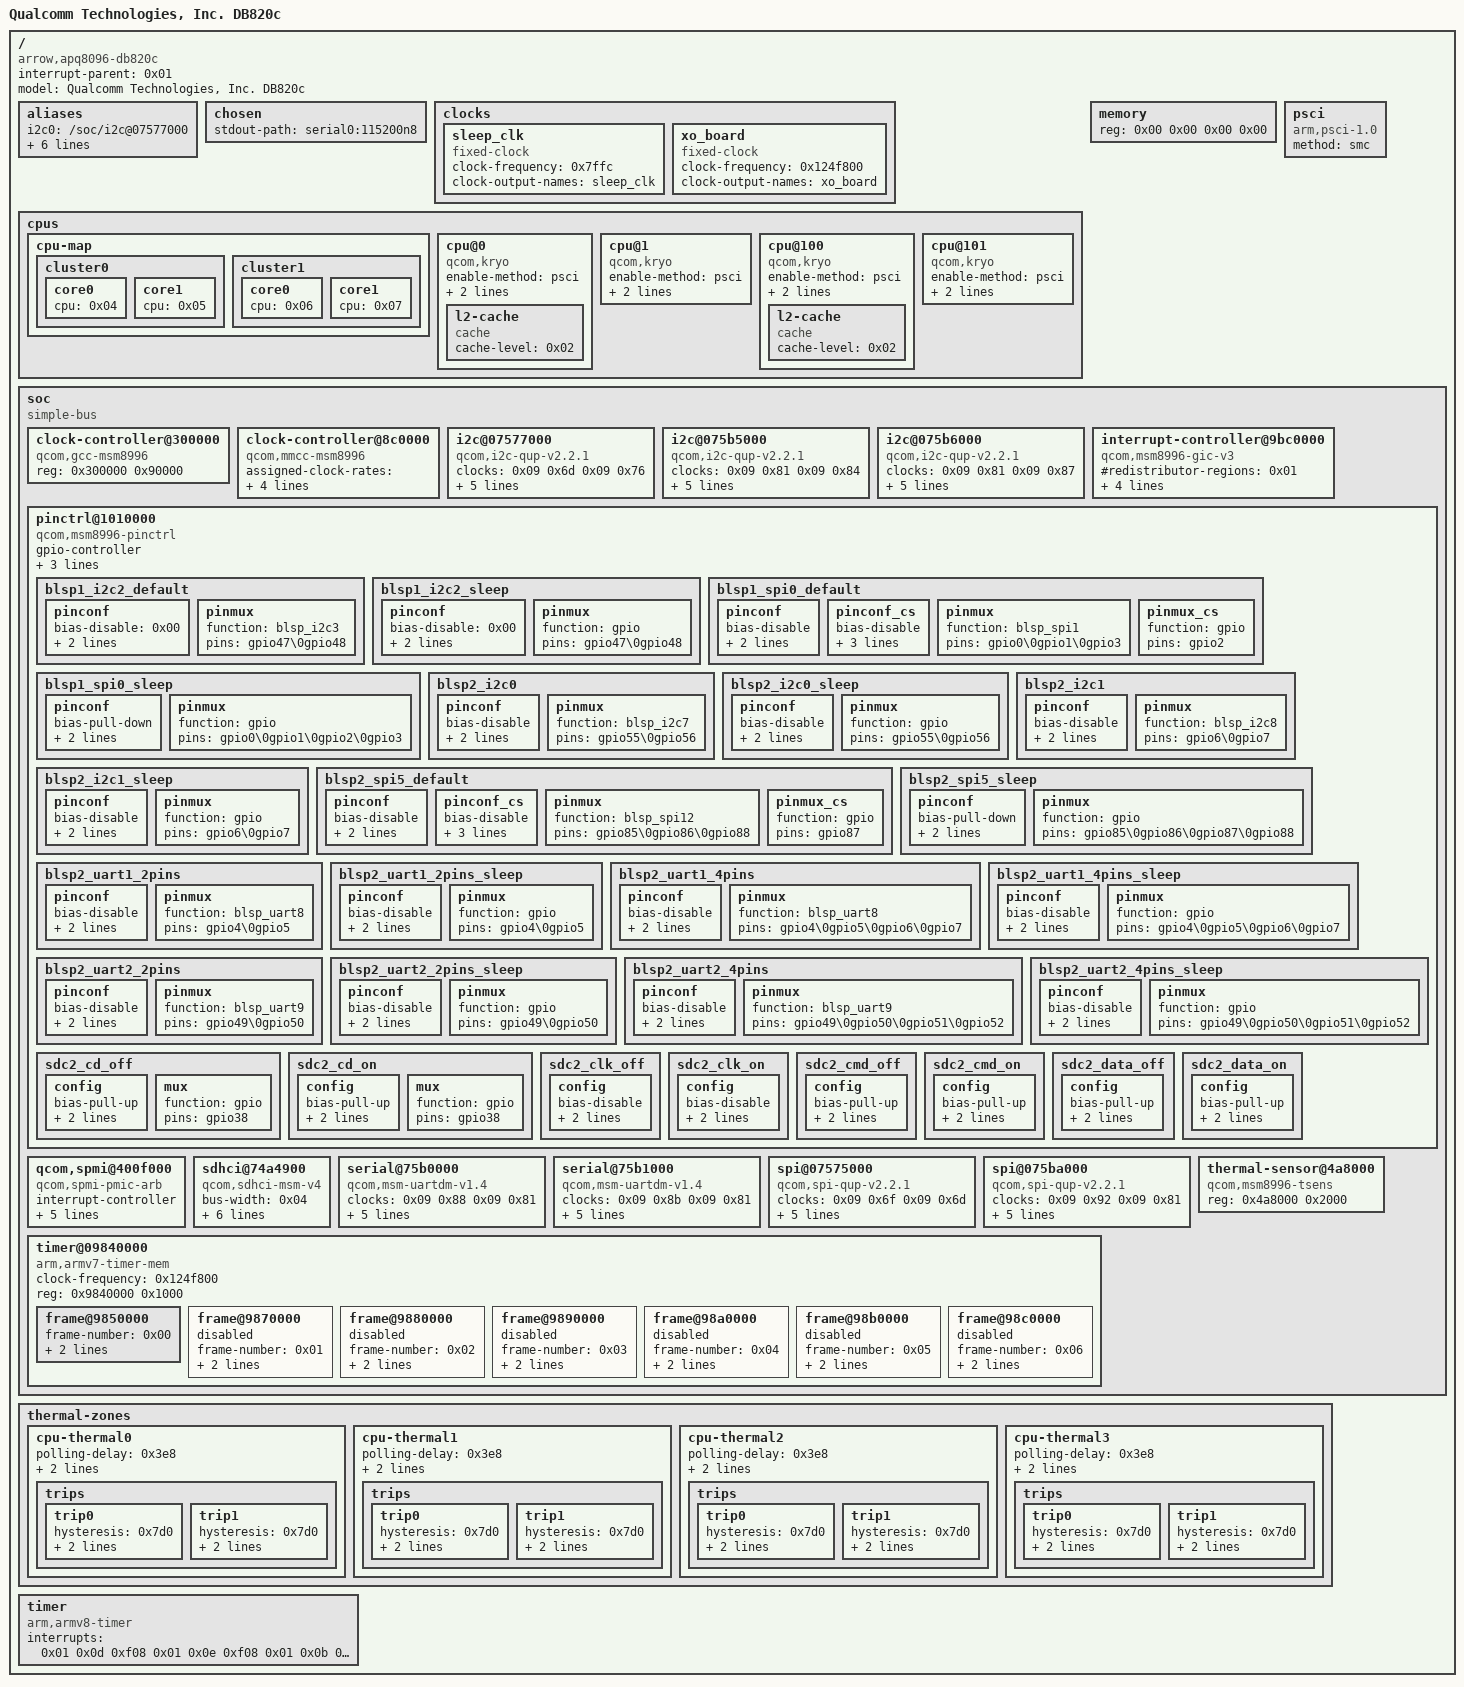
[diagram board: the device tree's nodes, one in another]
/dts-v1/;

/ {
	#address-cells = <0x02>;
	#size-cells = <0x02>;
	compatible = "arrow,apq8096-db820c\0qcom,apq8096-sbc";
	interrupt-parent = <0x01>;
	model = "Qualcomm Technologies, Inc. DB820c";

	__symbols__ {
		CPU0 = "/cpus/cpu@0";
		CPU1 = "/cpus/cpu@1";
		CPU2 = "/cpus/cpu@100";
		CPU3 = "/cpus/cpu@101";
		L2_0 = "/cpus/cpu@0/l2-cache";
		L2_1 = "/cpus/cpu@100/l2-cache";
		blsp1_i2c2 = "/soc/i2c@07577000";
		blsp1_i2c2_default = "/soc/pinctrl@1010000/blsp1_i2c2_default";
		blsp1_i2c2_sleep = "/soc/pinctrl@1010000/blsp1_i2c2_sleep";
		blsp1_spi0 = "/soc/spi@07575000";
		blsp1_spi0_default = "/soc/pinctrl@1010000/blsp1_spi0_default";
		blsp1_spi0_sleep = "/soc/pinctrl@1010000/blsp1_spi0_sleep";
		blsp2_i2c0 = "/soc/i2c@075b5000";
		blsp2_i2c0_default = "/soc/pinctrl@1010000/blsp2_i2c0";
		blsp2_i2c0_sleep = "/soc/pinctrl@1010000/blsp2_i2c0_sleep";
		blsp2_i2c1 = "/soc/i2c@075b6000";
		blsp2_i2c1_default = "/soc/pinctrl@1010000/blsp2_i2c1";
		blsp2_i2c1_sleep = "/soc/pinctrl@1010000/blsp2_i2c1_sleep";
		blsp2_spi5 = "/soc/spi@075ba000";
		blsp2_spi5_default = "/soc/pinctrl@1010000/blsp2_spi5_default";
		blsp2_spi5_sleep = "/soc/pinctrl@1010000/blsp2_spi5_sleep";
		blsp2_uart1 = "/soc/serial@75b0000";
		blsp2_uart1_2pins_default = "/soc/pinctrl@1010000/blsp2_uart1_2pins";
		blsp2_uart1_2pins_sleep = "/soc/pinctrl@1010000/blsp2_uart1_2pins_sleep";
		blsp2_uart1_4pins_default = "/soc/pinctrl@1010000/blsp2_uart1_4pins";
		blsp2_uart1_4pins_sleep = "/soc/pinctrl@1010000/blsp2_uart1_4pins_sleep";
		blsp2_uart2 = "/soc/serial@75b1000";
		blsp2_uart2_2pins_default = "/soc/pinctrl@1010000/blsp2_uart2_2pins";
		blsp2_uart2_2pins_sleep = "/soc/pinctrl@1010000/blsp2_uart2_2pins_sleep";
		blsp2_uart2_4pins_default = "/soc/pinctrl@1010000/blsp2_uart2_4pins";
		blsp2_uart2_4pins_sleep = "/soc/pinctrl@1010000/blsp2_uart2_4pins_sleep";
		cpu_alert0 = "/thermal-zones/cpu-thermal0/trips/trip0";
		cpu_alert1 = "/thermal-zones/cpu-thermal1/trips/trip0";
		cpu_alert2 = "/thermal-zones/cpu-thermal2/trips/trip0";
		cpu_alert3 = "/thermal-zones/cpu-thermal3/trips/trip0";
		cpu_crit0 = "/thermal-zones/cpu-thermal0/trips/trip1";
		cpu_crit1 = "/thermal-zones/cpu-thermal1/trips/trip1";
		cpu_crit2 = "/thermal-zones/cpu-thermal2/trips/trip1";
		cpu_crit3 = "/thermal-zones/cpu-thermal3/trips/trip1";
		gcc = "/soc/clock-controller@300000";
		intc = "/soc/interrupt-controller@9bc0000";
		mmcc = "/soc/clock-controller@8c0000";
		msmgpio = "/soc/pinctrl@1010000";
		sdc2_cd_off = "/soc/pinctrl@1010000/sdc2_cd_off";
		sdc2_cd_on = "/soc/pinctrl@1010000/sdc2_cd_on";
		sdc2_clk_off = "/soc/pinctrl@1010000/sdc2_clk_off";
		sdc2_clk_on = "/soc/pinctrl@1010000/sdc2_clk_on";
		sdc2_cmd_off = "/soc/pinctrl@1010000/sdc2_cmd_off";
		sdc2_cmd_on = "/soc/pinctrl@1010000/sdc2_cmd_on";
		sdc2_data_off = "/soc/pinctrl@1010000/sdc2_data_off";
		sdc2_data_on = "/soc/pinctrl@1010000/sdc2_data_on";
		sdhc2 = "/soc/sdhci@74a4900";
		soc = "/soc";
		spmi_bus = "/soc/qcom,spmi@400f000";
		tsens0 = "/soc/thermal-sensor@4a8000";
	};

	aliases {
		i2c0 = "/soc/i2c@07577000";
		i2c1 = "/soc/i2c@075b6000";
		i2c2 = "/soc/i2c@075b5000";
		serial0 = "/soc/serial@75b0000";
		serial1 = "/soc/serial@75b1000";
		spi0 = "/soc/spi@07575000";
		spi1 = "/soc/spi@075ba000";
	};

	chosen {
		stdout-path = "serial0:115200n8";
	};

	clocks {

		sleep_clk {
			#clock-cells = <0x00>;
			clock-frequency = <0x7ffc>;
			clock-output-names = "sleep_clk";
			compatible = "fixed-clock";
		};

		xo_board {
			#clock-cells = <0x00>;
			clock-frequency = <0x124f800>;
			clock-output-names = "xo_board";
			compatible = "fixed-clock";
		};
	};

	cpus {
		#address-cells = <0x02>;
		#size-cells = <0x00>;

		cpu-map {

			cluster0 {

				core0 {
					cpu = <0x04>;
				};

				core1 {
					cpu = <0x05>;
				};
			};

			cluster1 {

				core0 {
					cpu = <0x06>;
				};

				core1 {
					cpu = <0x07>;
				};
			};
		};

		cpu@0 {
			compatible = "qcom,kryo";
			device_type = "cpu";
			enable-method = "psci";
			next-level-cache = <0x02>;
			phandle = <0x04>;
			reg = <0x00 0x00>;

			l2-cache {
				cache-level = <0x02>;
				compatible = "cache";
				phandle = <0x02>;
			};
		};

		cpu@1 {
			compatible = "qcom,kryo";
			device_type = "cpu";
			enable-method = "psci";
			next-level-cache = <0x02>;
			phandle = <0x05>;
			reg = <0x00 0x01>;
		};

		cpu@100 {
			compatible = "qcom,kryo";
			device_type = "cpu";
			enable-method = "psci";
			next-level-cache = <0x03>;
			phandle = <0x06>;
			reg = <0x00 0x100>;

			l2-cache {
				cache-level = <0x02>;
				compatible = "cache";
				phandle = <0x03>;
			};
		};

		cpu@101 {
			compatible = "qcom,kryo";
			device_type = "cpu";
			enable-method = "psci";
			next-level-cache = <0x03>;
			phandle = <0x07>;
			reg = <0x00 0x101>;
		};
	};

	memory {
		device_type = "memory";
		reg = <0x00 0x00 0x00 0x00>;
	};

	psci {
		compatible = "arm,psci-1.0";
		method = "smc";
	};

	soc {
		#address-cells = <0x01>;
		#size-cells = <0x01>;
		compatible = "simple-bus";
		phandle = <0x2a>;
		ranges = <0x00 0x00 0x00 0xffffffff>;

		clock-controller@300000 {
			#clock-cells = <0x01>;
			#power-domain-cells = <0x01>;
			#reset-cells = <0x01>;
			compatible = "qcom,gcc-msm8996";
			phandle = <0x09>;
			reg = <0x300000 0x90000>;
		};

		clock-controller@8c0000 {
			#clock-cells = <0x01>;
			#power-domain-cells = <0x01>;
			#reset-cells = <0x01>;
			assigned-clock-rates = <0x25317c00 0x30479e80 0x3a699d00 0x39387000 0x312c8040>;
			assigned-clocks = <0x21 0x0f 0x21 0x03 0x21 0x07 0x21 0x09 0x21 0x0b>;
			compatible = "qcom,mmcc-msm8996";
			phandle = <0x21>;
			reg = <0x8c0000 0x40000>;
		};

		i2c@07577000 {
			#address-cells = <0x01>;
			#size-cells = <0x00>;
			clock-names = "iface\0core";
			clocks = <0x09 0x6d 0x09 0x76>;
			compatible = "qcom,i2c-qup-v2.2.1";
			interrupts = <0x00 0x61 0x00>;
			label = "LS-I2C0";
			phandle = <0x30>;
			pinctrl-0 = <0x14>;
			pinctrl-1 = <0x15>;
			pinctrl-names = "default\0sleep";
			reg = <0x7577000 0x1000>;
			status = "okay";
		};

		i2c@075b5000 {
			#address-cells = <0x01>;
			#size-cells = <0x00>;
			clock-names = "iface\0core";
			clocks = <0x09 0x81 0x09 0x84>;
			compatible = "qcom,i2c-qup-v2.2.1";
			interrupts = <0x00 0x65 0x00>;
			label = "HS-I2C2";
			phandle = <0x2c>;
			pinctrl-0 = <0x0c>;
			pinctrl-1 = <0x0d>;
			pinctrl-names = "default\0sleep";
			reg = <0x75b5000 0x1000>;
			status = "okay";
		};

		i2c@075b6000 {
			#address-cells = <0x01>;
			#size-cells = <0x00>;
			clock-names = "iface\0core";
			clocks = <0x09 0x81 0x09 0x87>;
			compatible = "qcom,i2c-qup-v2.2.1";
			interrupts = <0x00 0x66 0x00>;
			label = "LS-I2C1";
			phandle = <0x2e>;
			pinctrl-0 = <0x10>;
			pinctrl-1 = <0x11>;
			pinctrl-names = "default\0sleep";
			reg = <0x75b6000 0x1000>;
			status = "okay";
		};

		interrupt-controller@9bc0000 {
			#interrupt-cells = <0x03>;
			#redistributor-regions = <0x01>;
			compatible = "qcom,msm8996-gic-v3\0arm,gic-v3";
			interrupt-controller;
			interrupts = <0x01 0x09 0x04>;
			phandle = <0x01>;
			redistributor-stride = <0x00 0x40000>;
			reg = <0x9bc0000 0x10000 0x9c00000 0x100000>;
		};

		pinctrl@1010000 {
			#gpio-cells = <0x02>;
			#interrupt-cells = <0x02>;
			compatible = "qcom,msm8996-pinctrl";
			gpio-controller;
			interrupt-controller;
			interrupts = <0x00 0xd0 0x04>;
			phandle = <0x20>;
			reg = <0x1010000 0x300000>;

			blsp1_i2c2_default {
				phandle = <0x14>;

				pinconf {
					bias-disable = <0x00>;
					drive-strength = <0x10>;
					pins = "gpio47\0gpio48";
				};

				pinmux {
					function = "blsp_i2c3";
					pins = "gpio47\0gpio48";
				};
			};

			blsp1_i2c2_sleep {
				phandle = <0x15>;

				pinconf {
					bias-disable = <0x00>;
					drive-strength = <0x02>;
					pins = "gpio47\0gpio48";
				};

				pinmux {
					function = "gpio";
					pins = "gpio47\0gpio48";
				};
			};

			blsp1_spi0_default {
				phandle = <0x0a>;

				pinconf {
					bias-disable;
					drive-strength = <0x0c>;
					pins = "gpio0\0gpio1\0gpio3";
				};

				pinconf_cs {
					bias-disable;
					drive-strength = <0x10>;
					output-high;
					pins = "gpio2";
				};

				pinmux {
					function = "blsp_spi1";
					pins = "gpio0\0gpio1\0gpio3";
				};

				pinmux_cs {
					function = "gpio";
					pins = "gpio2";
				};
			};

			blsp1_spi0_sleep {
				phandle = <0x0b>;

				pinconf {
					bias-pull-down;
					drive-strength = <0x02>;
					pins = "gpio0\0gpio1\0gpio2\0gpio3";
				};

				pinmux {
					function = "gpio";
					pins = "gpio0\0gpio1\0gpio2\0gpio3";
				};
			};

			blsp2_i2c0 {
				phandle = <0x0c>;

				pinconf {
					bias-disable;
					drive-strength = <0x10>;
					pins = "gpio55\0gpio56";
				};

				pinmux {
					function = "blsp_i2c7";
					pins = "gpio55\0gpio56";
				};
			};

			blsp2_i2c0_sleep {
				phandle = <0x0d>;

				pinconf {
					bias-disable;
					drive-strength = <0x02>;
					pins = "gpio55\0gpio56";
				};

				pinmux {
					function = "gpio";
					pins = "gpio55\0gpio56";
				};
			};

			blsp2_i2c1 {
				phandle = <0x10>;

				pinconf {
					bias-disable;
					drive-strength = <0x10>;
					pins = "gpio6\0gpio7";
				};

				pinmux {
					function = "blsp_i2c8";
					pins = "gpio6\0gpio7";
				};
			};

			blsp2_i2c1_sleep {
				phandle = <0x11>;

				pinconf {
					bias-disable;
					drive-strength = <0x02>;
					pins = "gpio6\0gpio7";
				};

				pinmux {
					function = "gpio";
					pins = "gpio6\0gpio7";
				};
			};

			blsp2_spi5_default {
				phandle = <0x16>;

				pinconf {
					bias-disable;
					drive-strength = <0x0c>;
					pins = "gpio85\0gpio86\0gpio88";
				};

				pinconf_cs {
					bias-disable;
					drive-strength = <0x10>;
					output-high;
					pins = "gpio87";
				};

				pinmux {
					function = "blsp_spi12";
					pins = "gpio85\0gpio86\0gpio88";
				};

				pinmux_cs {
					function = "gpio";
					pins = "gpio87";
				};
			};

			blsp2_spi5_sleep {
				phandle = <0x17>;

				pinconf {
					bias-pull-down;
					drive-strength = <0x02>;
					pins = "gpio85\0gpio86\0gpio87\0gpio88";
				};

				pinmux {
					function = "gpio";
					pins = "gpio85\0gpio86\0gpio87\0gpio88";
				};
			};

			blsp2_uart1_2pins {
				phandle = <0x0e>;

				pinconf {
					bias-disable;
					drive-strength = <0x10>;
					pins = "gpio4\0gpio5";
				};

				pinmux {
					function = "blsp_uart8";
					pins = "gpio4\0gpio5";
				};
			};

			blsp2_uart1_2pins_sleep {
				phandle = <0x0f>;

				pinconf {
					bias-disable;
					drive-strength = <0x02>;
					pins = "gpio4\0gpio5";
				};

				pinmux {
					function = "gpio";
					pins = "gpio4\0gpio5";
				};
			};

			blsp2_uart1_4pins {
				phandle = <0x33>;

				pinconf {
					bias-disable;
					drive-strength = <0x10>;
					pins = "gpio4\0gpio5\0gpio6\0gpio7";
				};

				pinmux {
					function = "blsp_uart8";
					pins = "gpio4\0gpio5\0gpio6\0gpio7";
				};
			};

			blsp2_uart1_4pins_sleep {
				phandle = <0x34>;

				pinconf {
					bias-disable;
					drive-strength = <0x02>;
					pins = "gpio4\0gpiio5\0gpio6\0gpio7";
				};

				pinmux {
					function = "gpio";
					pins = "gpio4\0gpio5\0gpio6\0gpio7";
				};
			};

			blsp2_uart2_2pins {
				phandle = <0x35>;

				pinconf {
					bias-disable;
					drive-strength = <0x10>;
					pins = "gpio49\0gpio50";
				};

				pinmux {
					function = "blsp_uart9";
					pins = "gpio49\0gpio50";
				};
			};

			blsp2_uart2_2pins_sleep {
				phandle = <0x36>;

				pinconf {
					bias-disable;
					drive-strength = <0x02>;
					pins = "gpio49\0gpio50";
				};

				pinmux {
					function = "gpio";
					pins = "gpio49\0gpio50";
				};
			};

			blsp2_uart2_4pins {
				phandle = <0x12>;

				pinconf {
					bias-disable;
					drive-strength = <0x10>;
					pins = "gpio49\0gpio50\0gpio51\0gpio52";
				};

				pinmux {
					function = "blsp_uart9";
					pins = "gpio49\0gpio50\0gpio51\0gpio52";
				};
			};

			blsp2_uart2_4pins_sleep {
				phandle = <0x13>;

				pinconf {
					bias-disable;
					drive-strength = <0x02>;
					pins = "gpio49\0gpio50\0gpio51\0gpio52";
				};

				pinmux {
					function = "gpio";
					pins = "gpio49\0gpio50\0gpio51\0gpio52";
				};
			};

			sdc2_cd_off {
				phandle = <0x1f>;

				config {
					bias-pull-up;
					drive-strength = <0x02>;
					pins = "gpio38";
				};

				mux {
					function = "gpio";
					pins = "gpio38";
				};
			};

			sdc2_cd_on {
				phandle = <0x1b>;

				config {
					bias-pull-up;
					drive-strength = <0x10>;
					pins = "gpio38";
				};

				mux {
					function = "gpio";
					pins = "gpio38";
				};
			};

			sdc2_clk_off {
				phandle = <0x1c>;

				config {
					bias-disable;
					drive-strength = <0x02>;
					pins = "sdc2_clk";
				};
			};

			sdc2_clk_on {
				phandle = <0x18>;

				config {
					bias-disable;
					drive-strength = <0x10>;
					pins = "sdc2_clk";
				};
			};

			sdc2_cmd_off {
				phandle = <0x1d>;

				config {
					bias-pull-up;
					drive-strength = <0x02>;
					pins = "sdc2_cmd";
				};
			};

			sdc2_cmd_on {
				phandle = <0x19>;

				config {
					bias-pull-up;
					drive-strength = <0x0a>;
					pins = "sdc2_cmd";
				};
			};

			sdc2_data_off {
				phandle = <0x1e>;

				config {
					bias-pull-up;
					drive-strength = <0x02>;
					pins = "sdc2_data";
				};
			};

			sdc2_data_on {
				phandle = <0x1a>;

				config {
					bias-pull-up;
					drive-strength = <0x0a>;
					pins = "sdc2_data";
				};
			};
		};

		qcom,spmi@400f000 {
			#address-cells = <0x02>;
			#interrupt-cells = <0x04>;
			#size-cells = <0x00>;
			compatible = "qcom,spmi-pmic-arb";
			interrupt-controller;
			interrupt-names = "periph_irq";
			interrupts = <0x00 0x146 0x04>;
			phandle = <0x37>;
			qcom,channel = <0x00>;
			qcom,ee = <0x00>;
			reg = <0x400f000 0x1000 0x4400000 0x800000 0x4c00000 0x800000 0x5800000 0x200000 0x400a000 0x2100>;
			reg-names = "core\0chnls\0obsrvr\0intr\0cnfg";
		};

		sdhci@74a4900 {
			bus-width = <0x04>;
			cd-gpios = <0x20 0x26 0x01>;
			clock-names = "iface\0core";
			clocks = <0x09 0x68 0x09 0x67>;
			compatible = "qcom,sdhci-msm-v4";
			interrupt-names = "hc_irq\0pwr_irq";
			interrupts = <0x00 0x7d 0x00 0x00 0xdd 0x00>;
			phandle = <0x32>;
			pinctrl-0 = <0x18 0x19 0x1a 0x1b>;
			pinctrl-1 = <0x1c 0x1d 0x1e 0x1f>;
			pinctrl-names = "default\0sleep";
			reg = <0x74a4900 0x314 0x74a4000 0x800>;
			reg-names = "hc_mem\0core_mem";
			status = "okay";
		};

		serial@75b0000 {
			clock-names = "core\0iface";
			clocks = <0x09 0x88 0x09 0x81>;
			compatible = "qcom,msm-uartdm-v1.4\0qcom,msm-uartdm";
			interrupts = <0x00 0x72 0x04>;
			label = "LS-UART1";
			phandle = <0x2d>;
			pinctrl-0 = <0x0e>;
			pinctrl-1 = <0x0f>;
			pinctrl-names = "default\0sleep";
			reg = <0x75b0000 0x1000>;
			status = "okay";
		};

		serial@75b1000 {
			clock-names = "core\0iface";
			clocks = <0x09 0x8b 0x09 0x81>;
			compatible = "qcom,msm-uartdm-v1.4\0qcom,msm-uartdm";
			interrupts = <0x00 0x73 0x04>;
			label = "LS-UART0";
			phandle = <0x2f>;
			pinctrl-0 = <0x12>;
			pinctrl-1 = <0x13>;
			pinctrl-names = "default\0sleep";
			reg = <0x75b1000 0x1000>;
			status = "okay";
		};

		spi@07575000 {
			#address-cells = <0x01>;
			#size-cells = <0x00>;
			clock-names = "core\0iface";
			clocks = <0x09 0x6f 0x09 0x6d>;
			compatible = "qcom,spi-qup-v2.2.1";
			interrupts = <0x00 0x5f 0x04>;
			label = "LS-SPI0";
			phandle = <0x2b>;
			pinctrl-0 = <0x0a>;
			pinctrl-1 = <0x0b>;
			pinctrl-names = "default\0sleep";
			reg = <0x7575000 0x600>;
			status = "okay";
		};

		spi@075ba000 {
			#address-cells = <0x01>;
			#size-cells = <0x00>;
			clock-names = "core\0iface";
			clocks = <0x09 0x92 0x09 0x81>;
			compatible = "qcom,spi-qup-v2.2.1";
			interrupts = <0x00 0x6a 0x04>;
			label = "HS-SPI1";
			phandle = <0x31>;
			pinctrl-0 = <0x16>;
			pinctrl-1 = <0x17>;
			pinctrl-names = "default\0sleep";
			reg = <0x75ba000 0x600>;
			status = "okay";
		};

		thermal-sensor@4a8000 {
			#thermal-sensor-cells = <0x01>;
			compatible = "qcom,msm8996-tsens";
			phandle = <0x08>;
			reg = <0x4a8000 0x2000>;
		};

		timer@09840000 {
			#address-cells = <0x01>;
			#size-cells = <0x01>;
			clock-frequency = <0x124f800>;
			compatible = "arm,armv7-timer-mem";
			ranges;
			reg = <0x9840000 0x1000>;

			frame@9850000 {
				frame-number = <0x00>;
				interrupts = <0x00 0x1f 0x04 0x00 0x1e 0x04>;
				reg = <0x9850000 0x1000 0x9860000 0x1000>;
			};

			frame@9870000 {
				frame-number = <0x01>;
				interrupts = <0x00 0x20 0x04>;
				reg = <0x9870000 0x1000>;
				status = "disabled";
			};

			frame@9880000 {
				frame-number = <0x02>;
				interrupts = <0x00 0x21 0x04>;
				reg = <0x9880000 0x1000>;
				status = "disabled";
			};

			frame@9890000 {
				frame-number = <0x03>;
				interrupts = <0x00 0x22 0x04>;
				reg = <0x9890000 0x1000>;
				status = "disabled";
			};

			frame@98a0000 {
				frame-number = <0x04>;
				interrupts = <0x00 0x23 0x04>;
				reg = <0x98a0000 0x1000>;
				status = "disabled";
			};

			frame@98b0000 {
				frame-number = <0x05>;
				interrupts = <0x00 0x24 0x04>;
				reg = <0x98b0000 0x1000>;
				status = "disabled";
			};

			frame@98c0000 {
				frame-number = <0x06>;
				interrupts = <0x00 0x25 0x04>;
				reg = <0x98c0000 0x1000>;
				status = "disabled";
			};
		};
	};

	thermal-zones {

		cpu-thermal0 {
			polling-delay = <0x3e8>;
			polling-delay-passive = <0xfa>;
			thermal-sensors = <0x08 0x03>;

			trips {

				trip0 {
					hysteresis = <0x7d0>;
					phandle = <0x22>;
					temperature = <0x124f8>;
					type = "passive";
				};

				trip1 {
					hysteresis = <0x7d0>;
					phandle = <0x23>;
					temperature = <0x1adb0>;
					type = "critical";
				};
			};
		};

		cpu-thermal1 {
			polling-delay = <0x3e8>;
			polling-delay-passive = <0xfa>;
			thermal-sensors = <0x08 0x05>;

			trips {

				trip0 {
					hysteresis = <0x7d0>;
					phandle = <0x24>;
					temperature = <0x124f8>;
					type = "passive";
				};

				trip1 {
					hysteresis = <0x7d0>;
					phandle = <0x25>;
					temperature = <0x1adb0>;
					type = "critical";
				};
			};
		};

		cpu-thermal2 {
			polling-delay = <0x3e8>;
			polling-delay-passive = <0xfa>;
			thermal-sensors = <0x08 0x08>;

			trips {

				trip0 {
					hysteresis = <0x7d0>;
					phandle = <0x26>;
					temperature = <0x124f8>;
					type = "passive";
				};

				trip1 {
					hysteresis = <0x7d0>;
					phandle = <0x27>;
					temperature = <0x1adb0>;
					type = "critical";
				};
			};
		};

		cpu-thermal3 {
			polling-delay = <0x3e8>;
			polling-delay-passive = <0xfa>;
			thermal-sensors = <0x08 0x0a>;

			trips {

				trip0 {
					hysteresis = <0x7d0>;
					phandle = <0x28>;
					temperature = <0x124f8>;
					type = "passive";
				};

				trip1 {
					hysteresis = <0x7d0>;
					phandle = <0x29>;
					temperature = <0x1adb0>;
					type = "critical";
				};
			};
		};
	};

	timer {
		compatible = "arm,armv8-timer";
		interrupts = <0x01 0x0d 0xf08 0x01 0x0e 0xf08 0x01 0x0b 0xf08 0x01 0x0a 0xf08>;
	};
};
